# dthe register map
Vendor: Texas Instruments
Peripheral module from a debugger description file (folder cc32).
Registers are 32-bit, access not given, no defined reset value unless marked. A register's access mark holds for its fields unless they carry their own. Offsets are as the file gives them; lines under a group give offsets from that group; [hi:lo] are bit positions; {n}, {i} and the like mark numbered series; 'fields as' and 'values as' point back to an identical list; <NAME> marks a mode.

## dthe
0x810 SHA_IM
0x814 SHA_RIS
0x818 SHA_MIS
0x81C SHA_IC
0x820 AES_IM
0x824 AES_RIS
0x828 AES_MIS
0x82C AES_IC
0x830 DES_IM
0x834 DES_RIS
0x838 DES_MIS
0x83C DES_IC
0xA00 EIP_CGCFG
0xA04 EIP_CGREQ
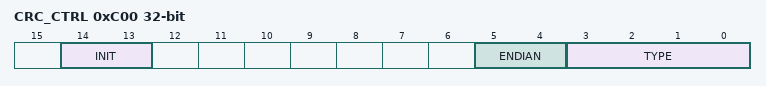
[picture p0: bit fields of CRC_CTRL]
0xC00 CRC_CTRL rw
  [14:13] INIT — Initialize the CRC 00 use SEED register context as starting value 10 all zero? 11 all one? This is self clearing. With first write to data register this value clears to zero and remain zero for rest of the operation unless written again
  [5:4] ENDIAN — Endian control [0] swap byte in half-word [1] swap half word
  [3:0] TYPE — Type of operation 0000 polynomial 0x8005 0001 polynomial 0x1021 0010 polynomial 0x4C11DB7 0011 polynomial 0x1EDC6F41 1000 TCP checksum TYPE in DTHE_S_CRC_CTRL & DTHE_S_CRC_CTRL should be exclusive
0xC10 CRC_SEED
0xC14 CRC_DIN
0xC18 CRC_RSLT_PP
{0xF00+4i} RAND_KEY{i} (i=0..3)
